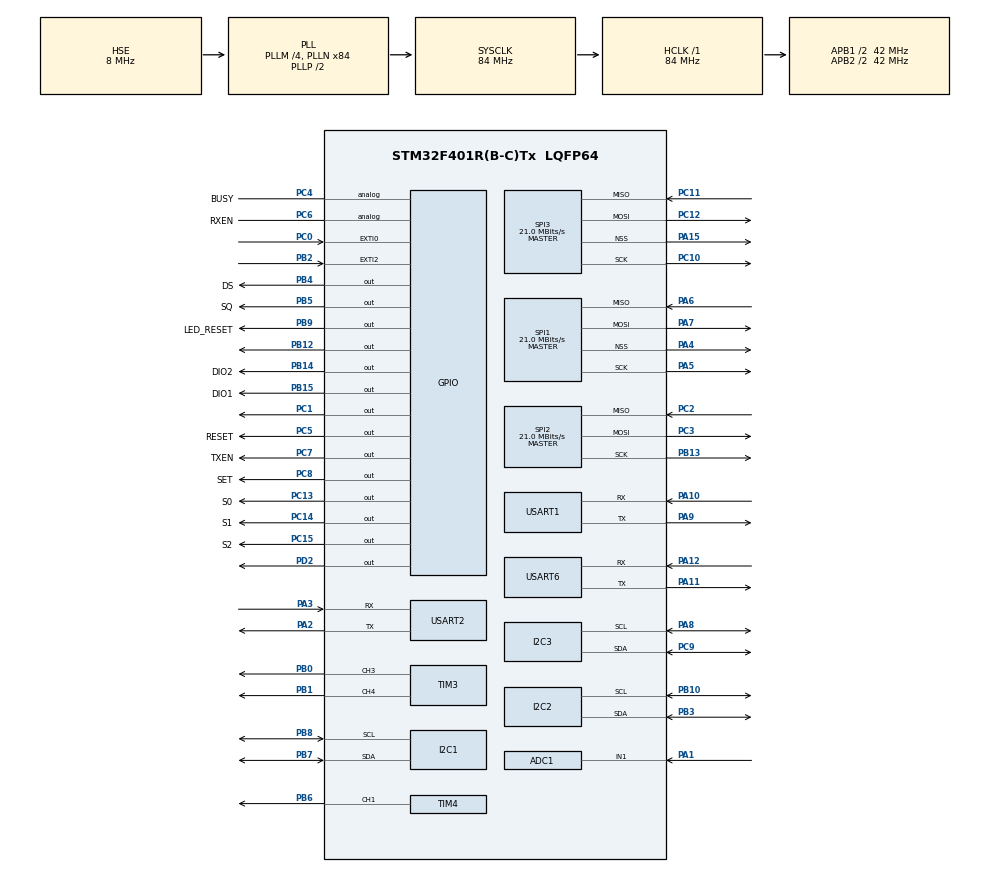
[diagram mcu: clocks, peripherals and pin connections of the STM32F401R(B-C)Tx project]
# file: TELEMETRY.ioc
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ADC1.Channel-0\#ChannelRegularConversion=ADC_CHANNEL_1
ADC1.NbrOfConversionFlag=1
ADC1.Rank-0\#ChannelRegularConversion=1
ADC1.SamplingTime-0\#ChannelRegularConversion=ADC_SAMPLETIME_3CYCLES
ADC1.master=1
FATFS._MAX_SS=4096
FATFS._USE_LFN=2
FREERTOS.Tasks01=defaultTask,24,128,StartDefaultTask,Default,NULL,Dynamic,NULL,NULL
Mcu.Family=STM32F4
Mcu.Name=STM32F401R(B-C)Tx
Mcu.Package=LQFP64
NVIC.EXTI0_IRQn=true\:5\:0\:false\:false\:true\:true\:true\:true\:true
NVIC.EXTI2_IRQn=true\:5\:0\:false\:false\:true\:true\:true\:true\:true
NVIC.PriorityGroup=NVIC_PRIORITYGROUP_4
PA0-WKUP.Signal=S_TIM2_CH1_ETR
PA1.Signal=ADCx_IN1
PA10.Mode=Asynchronous
PA10.Signal=USART1_RX
PA11.Mode=Asynchronous
PA11.Signal=USART6_TX
PA12.Mode=Asynchronous
PA12.Signal=USART6_RX
PA13.Mode=Serial_Wire
PA13.Signal=SYS_JTMS-SWDIO
PA14.Mode=Serial_Wire
PA14.Signal=SYS_JTCK-SWCLK
PA15.Mode=NSS_Signal_Hard_Output
PA15.Signal=SPI3_NSS
PA2.Mode=Asynchronous
PA2.Signal=USART2_TX
PA3.Mode=Asynchronous
PA3.Signal=USART2_RX
PA4.Mode=NSS_Signal_Hard_Output
PA4.Signal=SPI1_NSS
PA5.Mode=Full_Duplex_Master
PA5.Signal=SPI1_SCK
PA6.Mode=Full_Duplex_Master
PA6.Signal=SPI1_MISO
PA7.Mode=Full_Duplex_Master
PA7.Signal=SPI1_MOSI
PA8.Mode=I2C
PA8.Signal=I2C3_SCL
PA9.Mode=Asynchronous
PA9.Signal=USART1_TX
PB0.Signal=S_TIM3_CH3
PB1.Signal=S_TIM3_CH4
PB10.Mode=I2C
PB10.Signal=I2C2_SCL
PB12.Signal=GPIO_Output
PB13.Mode=Full_Duplex_Master
PB13.Signal=SPI2_SCK
PB14.GPIO_Label=DIO2
PB14.Signal=GPIO_Output
PB15.GPIO_Label=DIO1
PB15.Signal=GPIO_Output
PB2.Signal=GPXTI2
PB3.Mode=I2C
PB3.Signal=I2C2_SDA
PB4.GPIO_Label=DS
PB4.Signal=GPIO_Output
PB5.GPIO_Label=SQ
PB5.Signal=GPIO_Output
PB6.Signal=S_TIM4_CH1
PB7.Mode=I2C
PB7.Signal=I2C1_SDA
PB8.Mode=I2C
PB8.Signal=I2C1_SCL
PB9.GPIO_Label=LED_RESET
PB9.Signal=GPIO_Output
PC0.Signal=GPXTI0
PC1.Signal=GPIO_Output
PC10.Mode=Full_Duplex_Master
PC10.Signal=SPI3_SCK
PC11.Mode=Full_Duplex_Master
PC11.Signal=SPI3_MISO
PC12.Mode=Full_Duplex_Master
PC12.Signal=SPI3_MOSI
PC13-ANTI_TAMP.GPIO_Label=S0
PC13-ANTI_TAMP.Signal=GPIO_Output
PC14-OSC32_IN.GPIO_Label=S1
PC14-OSC32_IN.Signal=GPIO_Output
PC15-OSC32_OUT.GPIO_Label=S2
PC15-OSC32_OUT.Signal=GPIO_Output
PC2.Mode=Full_Duplex_Master
PC2.Signal=SPI2_MISO
PC3.Mode=Full_Duplex_Master
PC3.Signal=SPI2_MOSI
PC4.GPIO_Label=BUSY
PC4.Signal=GPIO_Analog
PC5.GPIO_Label=RESET
PC5.Signal=GPIO_Output
PC6.GPIO_Label=RXEN
PC6.Signal=GPIO_Analog
PC7.GPIO_Label=TXEN
PC7.Signal=GPIO_Output
PC8.GPIO_Label=SET
PC8.Signal=GPIO_Output
PC9.Mode=I2C
PC9.Signal=I2C3_SDA
PD2.Signal=GPIO_Output
PH0\ -\ OSC_IN.Mode=HSE-External-Oscillator
PH0\ -\ OSC_IN.Signal=RCC_OSC_IN
PH1\ -\ OSC_OUT.Mode=HSE-External-Oscillator
PH1\ -\ OSC_OUT.Signal=RCC_OSC_OUT
ProjectManager.HeapSize=0x200
ProjectManager.StackSize=0x400
ProjectManager.TargetToolchain=STM32CubeIDE
RCC.48MHZClocksFreq_Value=42000000
RCC.AHBFreq_Value=84000000
RCC.APB1CLKDivider=RCC_HCLK_DIV2
RCC.APB1Freq_Value=42000000
RCC.APB1TimFreq_Value=84000000
RCC.APB2CLKDivider=RCC_HCLK_DIV2
RCC.APB2Freq_Value=42000000
RCC.APB2TimFreq_Value=84000000
RCC.CortexFreq_Value=84000000
RCC.HCLKFreq_Value=84000000
RCC.HSE_VALUE=8000000
RCC.HSI_VALUE=16000000
RCC.LSE_VALUE=32768
RCC.PLLM=4
RCC.PLLN=84
RCC.PLLSourceVirtual=RCC_PLLSOURCE_HSE
RCC.SYSCLKFreq_VALUE=84000000
RCC.SYSCLKSource=RCC_SYSCLKSOURCE_PLLCLK
RCC.VCOOutputFreq_Value=168000000
SH.ADCx_IN1.0=ADC1_IN1,IN1
SH.S_TIM2_CH1_ETR.0=TIM2_CH1
SH.S_TIM3_CH3.0=TIM3_CH3,PWM Generation3 CH3
SH.S_TIM3_CH4.0=TIM3_CH4,PWM Generation4 CH4
SH.S_TIM4_CH1.0=TIM4_CH1,PWM Generation1 CH1
SPI1.CalculateBaudRate=21.0 MBits/s
SPI1.Direction=SPI_DIRECTION_2LINES
SPI1.Mode=SPI_MODE_MASTER
SPI1.VirtualNSS=VM_NSSHARD
SPI1.VirtualType=VM_MASTER
SPI2.BaudRatePrescaler=SPI_BAUDRATEPRESCALER_2
SPI2.CalculateBaudRate=21.0 MBits/s
SPI2.Direction=SPI_DIRECTION_2LINES
SPI2.Mode=SPI_MODE_MASTER
SPI2.VirtualType=VM_MASTER
SPI3.CalculateBaudRate=21.0 MBits/s
SPI3.Direction=SPI_DIRECTION_2LINES
SPI3.Mode=SPI_MODE_MASTER
SPI3.VirtualNSS=VM_NSSHARD
SPI3.VirtualType=VM_MASTER
TIM3.Channel-PWM\ Generation3\ CH3=TIM_CHANNEL_3
TIM3.Channel-PWM\ Generation4\ CH4=TIM_CHANNEL_4
TIM4.Channel-PWM\ Generation1\ CH1=TIM_CHANNEL_1
USART1.VirtualMode=VM_ASYNC
USART2.VirtualMode=VM_ASYNC
USART6.VirtualMode=VM_ASYNC
VP_FATFS_VS_Generic.Mode=User_defined
VP_FREERTOS_VS_CMSIS_V2.Mode=CMSIS_V2
board=custom

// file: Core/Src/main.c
/* USER CODE BEGIN Header */
/**
  ******************************************************************************
  * @file           : main.c
  * @brief          : Main program body
  ******************************************************************************
  * @attention
  *
  * Copyright (c) 2023 STMicroelectronics.
  * All rights reserved.
  *
  * This software is licensed under terms that can be found in the LICENSE file
  * in the root directory of this software component.
  * If no LICENSE file comes with this software, it is provided AS-IS.
  *
  ******************************************************************************
  */
/* USER CODE END Header */
#include "main.h"
#include "cmsis_os.h"

ADC_HandleTypeDef hadc1;

I2C_HandleTypeDef hi2c1;
I2C_HandleTypeDef hi2c2;
I2C_HandleTypeDef hi2c3;

SPI_HandleTypeDef hspi1;
SPI_HandleTypeDef hspi2;
SPI_HandleTypeDef hspi3;

TIM_HandleTypeDef htim3;
TIM_HandleTypeDef htim4;

UART_HandleTypeDef huart1;
UART_HandleTypeDef huart2;
UART_HandleTypeDef huart6;

/* Definitions for defaultTask */
osThreadId_t defaultTaskHandle;
const osThreadAttr_t defaultTask_attributes = {
  .name = "defaultTask",
  .stack_size = 128 * 4,
  .priority = (osPriority_t) osPriorityNormal,
};

void SystemClock_Config(void);
static void MX_GPIO_Init(void);
static void MX_ADC1_Init(void);
static void MX_I2C1_Init(void);
static void MX_I2C2_Init(void);
static void MX_I2C3_Init(void);
static void MX_SPI1_Init(void);
static void MX_SPI2_Init(void);
static void MX_SPI3_Init(void);
static void MX_TIM3_Init(void);
static void MX_TIM4_Init(void);
static void MX_USART1_UART_Init(void);
static void MX_USART2_UART_Init(void);
static void MX_USART6_UART_Init(void);
void StartDefaultTask(void *argument);

int main(void)
{

  /* MCU Configuration--------------------------------------------------------*/

  /* Reset of all peripherals, Initializes the Flash interface and the Systick. */
  HAL_Init();

  /* Configure the system clock */
  SystemClock_Config();

  /* Initialize all configured peripherals */
  MX_GPIO_Init();
  MX_ADC1_Init();
  MX_I2C1_Init();
  MX_I2C2_Init();
  MX_I2C3_Init();
  MX_SPI1_Init();
  MX_SPI2_Init();
  MX_SPI3_Init();
  MX_TIM3_Init();
  MX_TIM4_Init();
  MX_USART1_UART_Init();
  MX_USART2_UART_Init();
  MX_USART6_UART_Init();
  MX_FATFS_Init();
  /* USER CODE BEGIN 2 */

  MAIN_App(); /* Jump Into Telemetry Code */

  /* USER CODE END 2 */

  /* Init scheduler */
  osKernelInitialize();

  /* Create the thread(s) */
  /* creation of defaultTask */
  defaultTaskHandle = osThreadNew(StartDefaultTask, NULL, &defaultTask_attributes);

  /* Start scheduler */
  osKernelStart();

  /* We should never get here as control is now taken by the scheduler */
  /* Infinite loop */
  while (1)
  {

  }
}

void SystemClock_Config(void)
{
  RCC_OscInitTypeDef RCC_OscInitStruct = {0};
  RCC_ClkInitTypeDef RCC_ClkInitStruct = {0};

  /** Configure the main internal regulator output voltage
  */
  __HAL_RCC_PWR_CLK_ENABLE();
  __HAL_PWR_VOLTAGESCALING_CONFIG(PWR_REGULATOR_VOLTAGE_SCALE2);

  /** Initializes the RCC Oscillators according to the specified parameters
  * in the RCC_OscInitTypeDef structure.
  */
  RCC_OscInitStruct.OscillatorType = RCC_OSCILLATORTYPE_HSE;
  RCC_OscInitStruct.HSEState = RCC_HSE_ON;
  RCC_OscInitStruct.PLL.PLLState = RCC_PLL_ON;
  RCC_OscInitStruct.PLL.PLLSource = RCC_PLLSOURCE_HSE;
  RCC_OscInitStruct.PLL.PLLM = 4;
  RCC_OscInitStruct.PLL.PLLN = 84;
  RCC_OscInitStruct.PLL.PLLP = RCC_PLLP_DIV2;
  RCC_OscInitStruct.PLL.PLLQ = 4;
  if (HAL_RCC_OscConfig(&RCC_OscInitStruct) != HAL_OK)
  {
    Error_Handler();
  }

  /** Initializes the CPU, AHB and APB buses clocks
  */
  RCC_ClkInitStruct.ClockType = RCC_CLOCKTYPE_HCLK|RCC_CLOCKTYPE_SYSCLK
                              |RCC_CLOCKTYPE_PCLK1|RCC_CLOCKTYPE_PCLK2;
  RCC_ClkInitStruct.SYSCLKSource = RCC_SYSCLKSOURCE_PLLCLK;
  RCC_ClkInitStruct.AHBCLKDivider = RCC_SYSCLK_DIV1;
  RCC_ClkInitStruct.APB1CLKDivider = RCC_HCLK_DIV2;
  RCC_ClkInitStruct.APB2CLKDivider = RCC_HCLK_DIV2;

  if (HAL_RCC_ClockConfig(&RCC_ClkInitStruct, FLASH_LATENCY_2) != HAL_OK)
  {
    Error_Handler();
  }
}

static void MX_ADC1_Init(void)
{

  ADC_ChannelConfTypeDef sConfig = {0};

  /** Configure the global features of the ADC (Clock, Resolution, Data Alignment and number of conversion)
  */
  hadc1.Instance = ADC1;
  hadc1.Init.ClockPrescaler = ADC_CLOCK_SYNC_PCLK_DIV2;
  hadc1.Init.Resolution = ADC_RESOLUTION_12B;
  hadc1.Init.ScanConvMode = DISABLE;
  hadc1.Init.ContinuousConvMode = DISABLE;
  hadc1.Init.DiscontinuousConvMode = DISABLE;
  hadc1.Init.ExternalTrigConvEdge = ADC_EXTERNALTRIGCONVEDGE_NONE;
  hadc1.Init.ExternalTrigConv = ADC_SOFTWARE_START;
  hadc1.Init.DataAlign = ADC_DATAALIGN_RIGHT;
  hadc1.Init.NbrOfConversion = 1;
  hadc1.Init.DMAContinuousRequests = DISABLE;
  hadc1.Init.EOCSelection = ADC_EOC_SINGLE_CONV;
  if (HAL_ADC_Init(&hadc1) != HAL_OK)
  {
    Error_Handler();
  }

  /** Configure for the selected ADC regular channel its corresponding rank in the sequencer and its sample time.
  */
  sConfig.Channel = ADC_CHANNEL_1;
  sConfig.Rank = 1;
  sConfig.SamplingTime = ADC_SAMPLETIME_3CYCLES;
  if (HAL_ADC_ConfigChannel(&hadc1, &sConfig) != HAL_OK)
  {
    Error_Handler();
  }

}

static void MX_I2C1_Init(void)
{

  hi2c1.Instance = I2C1;
  hi2c1.Init.ClockSpeed = 100000;
  hi2c1.Init.DutyCycle = I2C_DUTYCYCLE_2;
  hi2c1.Init.OwnAddress1 = 0;
  hi2c1.Init.AddressingMode = I2C_ADDRESSINGMODE_7BIT;
  hi2c1.Init.DualAddressMode = I2C_DUALADDRESS_DISABLE;
  hi2c1.Init.OwnAddress2 = 0;
  hi2c1.Init.GeneralCallMode = I2C_GENERALCALL_DISABLE;
  hi2c1.Init.NoStretchMode = I2C_NOSTRETCH_DISABLE;
  if (HAL_I2C_Init(&hi2c1) != HAL_OK)
  {
    Error_Handler();
  }

}

static void MX_I2C2_Init(void)
{

  hi2c2.Instance = I2C2;
  hi2c2.Init.ClockSpeed = 100000;
  hi2c2.Init.DutyCycle = I2C_DUTYCYCLE_2;
  hi2c2.Init.OwnAddress1 = 0;
  hi2c2.Init.AddressingMode = I2C_ADDRESSINGMODE_7BIT;
  hi2c2.Init.DualAddressMode = I2C_DUALADDRESS_DISABLE;
  hi2c2.Init.OwnAddress2 = 0;
  hi2c2.Init.GeneralCallMode = I2C_GENERALCALL_DISABLE;
  hi2c2.Init.NoStretchMode = I2C_NOSTRETCH_DISABLE;
  if (HAL_I2C_Init(&hi2c2) != HAL_OK)
  {
    Error_Handler();
  }

}

static void MX_I2C3_Init(void)
{

  hi2c3.Instance = I2C3;
  hi2c3.Init.ClockSpeed = 100000;
  hi2c3.Init.DutyCycle = I2C_DUTYCYCLE_2;
  hi2c3.Init.OwnAddress1 = 0;
  hi2c3.Init.AddressingMode = I2C_ADDRESSINGMODE_7BIT;
  hi2c3.Init.DualAddressMode = I2C_DUALADDRESS_DISABLE;
  hi2c3.Init.OwnAddress2 = 0;
  hi2c3.Init.GeneralCallMode = I2C_GENERALCALL_DISABLE;
  hi2c3.Init.NoStretchMode = I2C_NOSTRETCH_DISABLE;
  if (HAL_I2C_Init(&hi2c3) != HAL_OK)
  {
    Error_Handler();
  }

}

static void MX_SPI1_Init(void)
{

  /* SPI1 parameter configuration*/
  hspi1.Instance = SPI1;
  hspi1.Init.Mode = SPI_MODE_MASTER;
  hspi1.Init.Direction = SPI_DIRECTION_2LINES;
  hspi1.Init.DataSize = SPI_DATASIZE_8BIT;
  hspi1.Init.CLKPolarity = SPI_POLARITY_LOW;
  hspi1.Init.CLKPhase = SPI_PHASE_1EDGE;
  hspi1.Init.NSS = SPI_NSS_HARD_OUTPUT;
  hspi1.Init.BaudRatePrescaler = SPI_BAUDRATEPRESCALER_2;
  hspi1.Init.FirstBit = SPI_FIRSTBIT_MSB;
  hspi1.Init.TIMode = SPI_TIMODE_DISABLE;
  hspi1.Init.CRCCalculation = SPI_CRCCALCULATION_DISABLE;
  hspi1.Init.CRCPolynomial = 10;
  if (HAL_SPI_Init(&hspi1) != HAL_OK)
  {
    Error_Handler();
  }

}

static void MX_SPI2_Init(void)
{

  /* SPI2 parameter configuration*/
  hspi2.Instance = SPI2;
  hspi2.Init.Mode = SPI_MODE_MASTER;
  hspi2.Init.Direction = SPI_DIRECTION_2LINES;
  hspi2.Init.DataSize = SPI_DATASIZE_8BIT;
  hspi2.Init.CLKPolarity = SPI_POLARITY_LOW;
  hspi2.Init.CLKPhase = SPI_PHASE_1EDGE;
  hspi2.Init.NSS = SPI_NSS_SOFT;
  hspi2.Init.BaudRatePrescaler = SPI_BAUDRATEPRESCALER_2;
  hspi2.Init.FirstBit = SPI_FIRSTBIT_MSB;
  hspi2.Init.TIMode = SPI_TIMODE_DISABLE;
  hspi2.Init.CRCCalculation = SPI_CRCCALCULATION_DISABLE;
  hspi2.Init.CRCPolynomial = 10;
  if (HAL_SPI_Init(&hspi2) != HAL_OK)
  {
    Error_Handler();
  }

}

static void MX_SPI3_Init(void)
{

  /* SPI3 parameter configuration*/
  hspi3.Instance = SPI3;
  hspi3.Init.Mode = SPI_MODE_MASTER;
  hspi3.Init.Direction = SPI_DIRECTION_2LINES;
  hspi3.Init.DataSize = SPI_DATASIZE_8BIT;
  hspi3.Init.CLKPolarity = SPI_POLARITY_LOW;
  hspi3.Init.CLKPhase = SPI_PHASE_1EDGE;
  hspi3.Init.NSS = SPI_NSS_HARD_OUTPUT;
  hspi3.Init.BaudRatePrescaler = SPI_BAUDRATEPRESCALER_2;
  hspi3.Init.FirstBit = SPI_FIRSTBIT_MSB;
  hspi3.Init.TIMode = SPI_TIMODE_DISABLE;
  hspi3.Init.CRCCalculation = SPI_CRCCALCULATION_DISABLE;
  hspi3.Init.CRCPolynomial = 10;
  if (HAL_SPI_Init(&hspi3) != HAL_OK)
  {
    Error_Handler();
  }

}

static void MX_TIM3_Init(void)
{

  TIM_MasterConfigTypeDef sMasterConfig = {0};
  TIM_OC_InitTypeDef sConfigOC = {0};

  htim3.Instance = TIM3;
  htim3.Init.Prescaler = 0;
  htim3.Init.CounterMode = TIM_COUNTERMODE_UP;
  htim3.Init.Period = 65535;
  htim3.Init.ClockDivision = TIM_CLOCKDIVISION_DIV1;
  htim3.Init.AutoReloadPreload = TIM_AUTORELOAD_PRELOAD_DISABLE;
  if (HAL_TIM_PWM_Init(&htim3) != HAL_OK)
  {
    Error_Handler();
  }
  sMasterConfig.MasterOutputTrigger = TIM_TRGO_RESET;
  sMasterConfig.MasterSlaveMode = TIM_MASTERSLAVEMODE_DISABLE;
  if (HAL_TIMEx_MasterConfigSynchronization(&htim3, &sMasterConfig) != HAL_OK)
  {
    Error_Handler();
  }
  sConfigOC.OCMode = TIM_OCMODE_PWM1;
  sConfigOC.Pulse = 0;
  sConfigOC.OCPolarity = TIM_OCPOLARITY_HIGH;
  sConfigOC.OCFastMode = TIM_OCFAST_DISABLE;
  if (HAL_TIM_PWM_ConfigChannel(&htim3, &sConfigOC, TIM_CHANNEL_3) != HAL_OK)
  {
    Error_Handler();
  }
  if (HAL_TIM_PWM_ConfigChannel(&htim3, &sConfigOC, TIM_CHANNEL_4) != HAL_OK)
  {
    Error_Handler();
  }
  HAL_TIM_MspPostInit(&htim3);

}

static void MX_TIM4_Init(void)
{

  TIM_MasterConfigTypeDef sMasterConfig = {0};
  TIM_OC_InitTypeDef sConfigOC = {0};

  htim4.Instance = TIM4;
  htim4.Init.Prescaler = 0;
  htim4.Init.CounterMode = TIM_COUNTERMODE_UP;
  htim4.Init.Period = 65535;
  htim4.Init.ClockDivision = TIM_CLOCKDIVISION_DIV1;
  htim4.Init.AutoReloadPreload = TIM_AUTORELOAD_PRELOAD_DISABLE;
  if (HAL_TIM_PWM_Init(&htim4) != HAL_OK)
  {
    Error_Handler();
  }
  sMasterConfig.MasterOutputTrigger = TIM_TRGO_RESET;
  sMasterConfig.MasterSlaveMode = TIM_MASTERSLAVEMODE_DISABLE;
  if (HAL_TIMEx_MasterConfigSynchronization(&htim4, &sMasterConfig) != HAL_OK)
  {
    Error_Handler();
  }
  sConfigOC.OCMode = TIM_OCMODE_PWM1;
  sConfigOC.Pulse = 0;
  sConfigOC.OCPolarity = TIM_OCPOLARITY_HIGH;
  sConfigOC.OCFastMode = TIM_OCFAST_DISABLE;
  if (HAL_TIM_PWM_ConfigChannel(&htim4, &sConfigOC, TIM_CHANNEL_1) != HAL_OK)
  {
    Error_Handler();
  }
  HAL_TIM_MspPostInit(&htim4);

}

static void MX_USART1_UART_Init(void)
{

  huart1.Instance = USART1;
  huart1.Init.BaudRate = 115200;
  huart1.Init.WordLength = UART_WORDLENGTH_8B;
  huart1.Init.StopBits = UART_STOPBITS_1;
  huart1.Init.Parity = UART_PARITY_NONE;
  huart1.Init.Mode = UART_MODE_TX_RX;
  huart1.Init.HwFlowCtl = UART_HWCONTROL_NONE;
  huart1.Init.OverSampling = UART_OVERSAMPLING_16;
  if (HAL_UART_Init(&huart1) != HAL_OK)
  {
    Error_Handler();
  }

}

static void MX_USART2_UART_Init(void)
{

  huart2.Instance = USART2;
  huart2.Init.BaudRate = 115200;
  huart2.Init.WordLength = UART_WORDLENGTH_8B;
  huart2.Init.StopBits = UART_STOPBITS_1;
  huart2.Init.Parity = UART_PARITY_NONE;
  huart2.Init.Mode = UART_MODE_TX_RX;
  huart2.Init.HwFlowCtl = UART_HWCONTROL_NONE;
  huart2.Init.OverSampling = UART_OVERSAMPLING_16;
  if (HAL_UART_Init(&huart2) != HAL_OK)
  {
    Error_Handler();
  }

}

static void MX_USART6_UART_Init(void)
{

  huart6.Instance = USART6;
  huart6.Init.BaudRate = 115200;
  huart6.Init.WordLength = UART_WORDLENGTH_8B;
  huart6.Init.StopBits = UART_STOPBITS_1;
  huart6.Init.Parity = UART_PARITY_NONE;
  huart6.Init.Mode = UART_MODE_TX_RX;
  huart6.Init.HwFlowCtl = UART_HWCONTROL_NONE;
  huart6.Init.OverSampling = UART_OVERSAMPLING_16;
  if (HAL_UART_Init(&huart6) != HAL_OK)
  {
    Error_Handler();
  }

}

static void MX_GPIO_Init(void)
{
  GPIO_InitTypeDef GPIO_InitStruct = {0};

  /* GPIO Ports Clock Enable */
  __HAL_RCC_GPIOC_CLK_ENABLE();
  __HAL_RCC_GPIOH_CLK_ENABLE();
  __HAL_RCC_GPIOA_CLK_ENABLE();
  __HAL_RCC_GPIOB_CLK_ENABLE();
  __HAL_RCC_GPIOD_CLK_ENABLE();

  /*Configure GPIO pin Output Level */
  HAL_GPIO_WritePin(GPIOC, S0_Pin|S1_Pin|S2_Pin|GPIO_PIN_1
                          |RESET_Pin|TXEN_Pin|SET_Pin, GPIO_PIN_RESET);

  /*Configure GPIO pin Output Level */
  HAL_GPIO_WritePin(GPIOB, GPIO_PIN_12|DIO2_Pin|DIO1_Pin|DS_Pin
                          |SQ_Pin|LED_RESET_Pin, GPIO_PIN_RESET);

  /*Configure GPIO pin Output Level */
  HAL_GPIO_WritePin(GPIOD, GPIO_PIN_2, GPIO_PIN_RESET);

  /*Configure GPIO pins : S0_Pin S1_Pin S2_Pin PC1
                           RESET_Pin TXEN_Pin SET_Pin */
  GPIO_InitStruct.Pin = S0_Pin|S1_Pin|S2_Pin|GPIO_PIN_1
                          |RESET_Pin|TXEN_Pin|SET_Pin;
  GPIO_InitStruct.Mode = GPIO_MODE_OUTPUT_PP;
  GPIO_InitStruct.Pull = GPIO_NOPULL;
  GPIO_InitStruct.Speed = GPIO_SPEED_FREQ_LOW;
  HAL_GPIO_Init(GPIOC, &GPIO_InitStruct);

  /*Configure GPIO pin : PC0 */
  GPIO_InitStruct.Pin = GPIO_PIN_0;
  GPIO_InitStruct.Mode = GPIO_MODE_IT_RISING;
  GPIO_InitStruct.Pull = GPIO_NOPULL;
  HAL_GPIO_Init(GPIOC, &GPIO_InitStruct);

  /*Configure GPIO pin : PA0 */
  GPIO_InitStruct.Pin = GPIO_PIN_0;
  GPIO_InitStruct.Mode = GPIO_MODE_AF_PP;
  GPIO_InitStruct.Pull = GPIO_NOPULL;
  GPIO_InitStruct.Speed = GPIO_SPEED_FREQ_LOW;
  GPIO_InitStruct.Alternate = GPIO_AF1_TIM2;
  HAL_GPIO_Init(GPIOA, &GPIO_InitStruct);

  /*Configure GPIO pins : BUSY_Pin RXEN_Pin */
  GPIO_InitStruct.Pin = BUSY_Pin|RXEN_Pin;
  GPIO_InitStruct.Mode = GPIO_MODE_ANALOG;
  GPIO_InitStruct.Pull = GPIO_NOPULL;
  HAL_GPIO_Init(GPIOC, &GPIO_InitStruct);

  /*Configure GPIO pin : PB2 */
  GPIO_InitStruct.Pin = GPIO_PIN_2;
  GPIO_InitStruct.Mode = GPIO_MODE_IT_RISING;
  GPIO_InitStruct.Pull = GPIO_NOPULL;
  HAL_GPIO_Init(GPIOB, &GPIO_InitStruct);

  /*Configure GPIO pins : PB12 DIO2_Pin DIO1_Pin DS_Pin
                           SQ_Pin LED_RESET_Pin */
  GPIO_InitStruct.Pin = GPIO_PIN_12|DIO2_Pin|DIO1_Pin|DS_Pin
                          |SQ_Pin|LED_RESET_Pin;
  GPIO_InitStruct.Mode = GPIO_MODE_OUTPUT_PP;
  GPIO_InitStruct.Pull = GPIO_NOPULL;
  GPIO_InitStruct.Speed = GPIO_SPEED_FREQ_LOW;
  HAL_GPIO_Init(GPIOB, &GPIO_InitStruct);

  /*Configure GPIO pin : PD2 */
  GPIO_InitStruct.Pin = GPIO_PIN_2;
  GPIO_InitStruct.Mode = GPIO_MODE_OUTPUT_PP;
  GPIO_InitStruct.Pull = GPIO_NOPULL;
  GPIO_InitStruct.Speed = GPIO_SPEED_FREQ_LOW;
  HAL_GPIO_Init(GPIOD, &GPIO_InitStruct);

  /* EXTI interrupt init*/
  HAL_NVIC_SetPriority(EXTI0_IRQn, 5, 0);
  HAL_NVIC_EnableIRQ(EXTI0_IRQn);

  HAL_NVIC_SetPriority(EXTI2_IRQn, 5, 0);
  HAL_NVIC_EnableIRQ(EXTI2_IRQn);

}

void StartDefaultTask(void *argument)
{
  for(;;)
  {
    osDelay(1);
  }
}

void Error_Handler(void)
{
  __disable_irq();
  while (1)
  {
  }
}
